AUTOSAR XML (schema 00048)
package /ComponentTypes
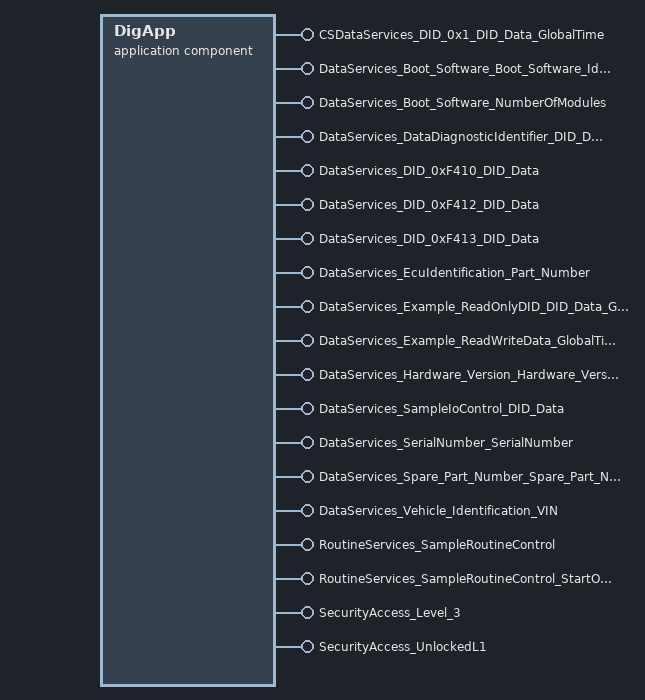
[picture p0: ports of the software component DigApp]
  application sw component type DigApp
    19 x provide port:
      CSDataServices_DID_0x1_DID_Data_GlobalTime: server-com-spec{operation=ReadData, queue-length=1}, provided-interface=CSDataServices_DID_0x1_DID_Data_GlobalTime
      DataServices_Boot_Software_Boot_Software_Identification: provided-interface=DataServices_Boot_Software_Boot_Software_Identification
        provided-com-specs:
          operation=WriteData, queue-length=1
          operation=ConditionCheckRead, queue-length=1
          operation=ReadData, queue-length=1
      DataServices_Boot_Software_NumberOfModules: provided-interface=DataServices_Boot_Software_NumberOfModules
        provided-com-specs:
          operation=WriteData, queue-length=1
          operation=ConditionCheckRead, queue-length=1
          operation=ReadData, queue-length=1
      DataServices_DataDiagnosticIdentifier_DID_DataDiagnosticIdentifier: provided-interface=DataServices_DataDiagnosticIdentifier_DID_DataDiagnosticIdentifier
        provided-com-specs:
          operation=WriteData, queue-length=1
          operation=ConditionCheckRead, queue-length=1
          operation=ReadData, queue-length=1
      DataServices_DID_0xF410_DID_Data: provided-com-specs=[{operation=ConditionCheckRead, queue-length=1}, {operation=ReadData, queue-length=1}], provided-interface=DataServices_DID_0xF410_DID_Data
      DataServices_DID_0xF412_DID_Data: provided-com-specs=[{operation=ConditionCheckRead, queue-length=1}, {operation=ReadData, queue-length=1}], provided-interface=DataServices_DID_0xF412_DID_Data
      DataServices_DID_0xF413_DID_Data: provided-com-specs=[{operation=ConditionCheckRead, queue-length=1}, {operation=ReadData, queue-length=1}], provided-interface=DataServices_DID_0xF413_DID_Data
      DataServices_EcuIdentification_Part_Number: provided-interface=DataServices_EcuIdentification_Part_Number
        provided-com-specs:
          operation=WriteData, queue-length=1
          operation=ConditionCheckRead, queue-length=1
          operation=ReadData, queue-length=1
      DataServices_Example_ReadOnlyDID_DID_Data_GlobalTime: provided-com-specs=[{operation=ConditionCheckRead, queue-length=1}, {operation=ReadData, queue-length=1}], provided-interface=DataServices_Example_ReadOnlyDID_DID_Data_GlobalTime
      DataServices_Example_ReadWriteData_GlobalTime: provided-interface=DataServices_Example_ReadWriteData_GlobalTime
        provided-com-specs:
          operation=WriteData, queue-length=1
          operation=ConditionCheckRead, queue-length=1
          operation=ReadData, queue-length=1
      DataServices_Hardware_Version_Hardware_Version_Number: provided-interface=DataServices_Hardware_Version_Hardware_Version_Number
        provided-com-specs:
          operation=WriteData, queue-length=1
          operation=ConditionCheckRead, queue-length=1
          operation=ReadData, queue-length=1
      DataServices_SampleIoControl_DID_Data: provided-interface=DataServices_SampleIoControl_DID_Data
        provided-com-specs:
          operation=ShortTermAdjustment, queue-length=1
          operation=FreezeCurrentState, queue-length=1
          operation=ResetToDefault, queue-length=1
          operation=ReturnControlToECU, queue-length=1
          operation=ReadData, queue-length=1
      DataServices_SerialNumber_SerialNumber: provided-interface=DataServices_SerialNumber_SerialNumber
        provided-com-specs:
          operation=WriteData, queue-length=1
          operation=ConditionCheckRead, queue-length=1
          operation=ReadData, queue-length=1
      DataServices_Spare_Part_Number_Spare_Part_Number: provided-interface=DataServices_Spare_Part_Number_Spare_Part_Number
        provided-com-specs:
          operation=WriteData, queue-length=1
          operation=ConditionCheckRead, queue-length=1
          operation=ReadData, queue-length=1
      DataServices_Vehicle_Identification_VIN: provided-interface=DataServices_Vehicle_Identification_VIN
        provided-com-specs:
          operation=WriteData, queue-length=1
          operation=ConditionCheckRead, queue-length=1
          operation=ReadData, queue-length=1
      RoutineServices_SampleRoutineControl: provided-interface=RoutineServices_SampleRoutineControl
        provided-com-specs:
          operation=RequestResults, queue-length=1
          operation=Stop, queue-length=1
          operation=Start, queue-length=1
      RoutineServices_SampleRoutineControl_StartOnly: provided-com-specs=[{operation=RequestResults, queue-length=1}, {operation=Start, queue-length=1}], provided-interface=RoutineServices_SampleRoutineControl_StartOnly
      SecurityAccess_Level_3: provided-com-specs=[{operation=CompareKey, queue-length=1}, {operation=GetSeed, queue-length=1}], provided-interface=SecurityAccess_Level_3
      SecurityAccess_UnlockedL1: provided-com-specs=[{operation=CompareKey, queue-length=1}, {operation=GetSeed, queue-length=1}], provided-interface=SecurityAccess_UnlockedL1
    behavior DigApp_InternalBehavior
      init event Dig_InitEvent: start-on-event=Dig_Init
      50 x operation invoked event:
        OIT_DataServices_Spare_Part_Number_Spare_Part_Number_WriteData_DataServices_Spare_Part_Number_Spare_Part_Number_WriteData: start-on-event=DataServices_Spare_Part_Number_Spare_Part_Number_WriteData, operation=DataServices_Spare_Part_Number_Spare_Part_Number.WriteData
        OIT_DataServices_Spare_Part_Number_Spare_Part_Number_ConditionCheckRead_DataServices_Spare_Part_Number_Spare_Part_NumberC28D5180: start-on-event=DataServices_Spare_Part_Number_Spare_Part_Number_ConditionCheckRead, operation=DataServices_Spare_Part_Number_Spare_Part_Number.ConditionCheckRead
        OIT_DataServices_Spare_Part_Number_Spare_Part_Number_ReadData_DataServices_Spare_Part_Number_Spare_Part_Number_ReadData: start-on-event=DataServices_Spare_Part_Number_Spare_Part_Number_ReadData, operation=DataServices_Spare_Part_Number_Spare_Part_Number.ReadData
        OIT_DataServices_Vehicle_Identification_VIN_WriteData_DataServices_Vehicle_Identification_VIN_WriteData: start-on-event=DataServices_Vehicle_Identification_VIN_WriteData, operation=DataServices_Vehicle_Identification_VIN.WriteData
        OIT_DataServices_Vehicle_Identification_VIN_ConditionCheckRead_DataServices_Vehicle_Identification_VIN_ConditionCheckRead: start-on-event=DataServices_Vehicle_Identification_VIN_ConditionCheckRead, operation=DataServices_Vehicle_Identification_VIN.ConditionCheckRead
        OIT_DataServices_Vehicle_Identification_VIN_ReadData_DataServices_Vehicle_Identification_VIN_ReadData: start-on-event=DataServices_Vehicle_Identification_VIN_ReadData, operation=DataServices_Vehicle_Identification_VIN.ReadData
        OIT_SecurityAccess_UnlockedL1_CompareKey_SecurityAccess_UnlockedL1_CompareKey: start-on-event=SecurityAccess_UnlockedL1_CompareKey, operation=SecurityAccess_UnlockedL1.CompareKey
        OIT_SecurityAccess_UnlockedL1_GetSeed_SecurityAccess_UnlockedL1_GetSeed: start-on-event=SecurityAccess_UnlockedL1_GetSeed, operation=SecurityAccess_UnlockedL1.GetSeed
        OIT_DataServices_DID_0xF413_DID_Data_ConditionCheckRead_DataServices_DID_0xF413_DID_Data_ConditionCheckRead: start-on-event=DataServices_DID_0xF413_DID_Data_ConditionCheckRead, operation=DataServices_DID_0xF413_DID_Data.ConditionCheckRead
        OIT_DataServices_DID_0xF413_DID_Data_ReadData_DataServices_DID_0xF413_DID_Data_ReadData: start-on-event=DataServices_DID_0xF413_DID_Data_ReadData, operation=DataServices_DID_0xF413_DID_Data.ReadData
        OIT_DataServices_Boot_Software_NumberOfModules_WriteData_DataServices_Boot_Software_NumberOfModules_WriteData: start-on-event=DataServices_Boot_Software_NumberOfModules_WriteData, operation=DataServices_Boot_Software_NumberOfModules.WriteData
        OIT_DataServices_Boot_Software_NumberOfModules_ConditionCheckRead_DataServices_Boot_Software_NumberOfModules_ConditionCheckRead: start-on-event=DataServices_Boot_Software_NumberOfModules_ConditionCheckRead, operation=DataServices_Boot_Software_NumberOfModules.ConditionCheckRead
        OIT_DataServices_Boot_Software_NumberOfModules_ReadData_DataServices_Boot_Software_NumberOfModules_ReadData: start-on-event=DataServices_Boot_Software_NumberOfModules_ReadData, operation=DataServices_Boot_Software_NumberOfModules.ReadData
        OIT_DataServices_DID_0xF412_DID_Data_ConditionCheckRead_DataServices_DID_0xF412_DID_Data_ConditionCheckRead: start-on-event=DataServices_DID_0xF412_DID_Data_ConditionCheckRead, operation=DataServices_DID_0xF412_DID_Data.ConditionCheckRead
        OIT_DataServices_DID_0xF412_DID_Data_ReadData_DataServices_DID_0xF412_DID_Data_ReadData: start-on-event=DataServices_DID_0xF412_DID_Data_ReadData, operation=DataServices_DID_0xF412_DID_Data.ReadData
        OIT_DataServices_SerialNumber_SerialNumber_WriteData_DataServices_SerialNumber_SerialNumber_WriteData: start-on-event=DataServices_SerialNumber_SerialNumber_WriteData, operation=DataServices_SerialNumber_SerialNumber.WriteData
        OIT_DataServices_SerialNumber_SerialNumber_ConditionCheckRead_DataServices_SerialNumber_SerialNumber_ConditionCheckRead: start-on-event=DataServices_SerialNumber_SerialNumber_ConditionCheckRead, operation=DataServices_SerialNumber_SerialNumber.ConditionCheckRead
        OIT_DataServices_SerialNumber_SerialNumber_ReadData_DataServices_SerialNumber_SerialNumber_ReadData: start-on-event=DataServices_SerialNumber_SerialNumber_ReadData, operation=DataServices_SerialNumber_SerialNumber.ReadData
        OIT_DataServices_DataDiagnosticIdentifier_DID_DataDiagnosticIdentifier_WriteData_DataServices_DataDiagnosticIdentifier_D1EF3D720: start-on-event=DataServices_DataDiagnosticIdentifier_DID_DataDiagnosticIdentifier_WriteData, operation=DataServices_DataDiagnosticIdentifier_DID_DataDiagnosticIdentifier.WriteData
        OIT_DataServices_DataDiagnosticIdentifier_DID_DataDiagnosticIdentifier_ConditionCheckRead_DataServices_DataDiagnosticIdeCC6C9644: start-on-event=DataServices_DataDiagnosticIdentifier_DID_DataDiagnosticIdentifier_ConditionCheckRead, operation=DataServices_DataDiagnosticIdentifier_DID_DataDiagnosticIdentifier.ConditionCheckRead
        OIT_DataServices_DataDiagnosticIdentifier_DID_DataDiagnosticIdentifier_ReadData_DataServices_DataDiagnosticIdentifier_DID8FC9525: start-on-event=DataServices_DataDiagnosticIdentifier_DID_DataDiagnosticIdentifier_ReadData, operation=DataServices_DataDiagnosticIdentifier_DID_DataDiagnosticIdentifier.ReadData
        OIT_DataServices_Hardware_Version_Hardware_Version_Number_WriteData_DataServices_Hardware_Version_Hardware_Version_Numbe125FF288: start-on-event=DataServices_Hardware_Version_Hardware_Version_Number_WriteData, operation=DataServices_Hardware_Version_Hardware_Version_Number.WriteData
        OIT_DataServices_Hardware_Version_Hardware_Version_Number_ConditionCheckRead_DataServices_Hardware_Version_Hardware_Vers10245F7A: start-on-event=DataServices_Hardware_Version_Hardware_Version_Number_ConditionCheckRead, operation=DataServices_Hardware_Version_Hardware_Version_Number.ConditionCheckRead
        OIT_DataServices_Hardware_Version_Hardware_Version_Number_ReadData_DataServices_Hardware_Version_Hardware_Version_Number62630144: start-on-event=DataServices_Hardware_Version_Hardware_Version_Number_ReadData, operation=DataServices_Hardware_Version_Hardware_Version_Number.ReadData
        OIT_CSDataServices_DID_0x1_DID_Data_GlobalTime_ReadData_CSDataServices_DID_0x1_DID_Data_GlobalTime_ReadData: start-on-event=CSDataServices_DID_0x1_DID_Data_GlobalTime_ReadData, operation=CSDataServices_DID_0x1_DID_Data_GlobalTime.ReadData
        OIT_RoutineServices_SampleRoutineControl_RequestResults_RoutineServices_SampleRoutineControl_RequestResults: start-on-event=RoutineServices_SampleRoutineControl_RequestResults, operation=RoutineServices_SampleRoutineControl.RequestResults
        OIT_RoutineServices_SampleRoutineControl_Stop_RoutineServices_SampleRoutineControl_Stop: start-on-event=RoutineServices_SampleRoutineControl_Stop, operation=RoutineServices_SampleRoutineControl.Stop
        OIT_RoutineServices_SampleRoutineControl_Start_RoutineServices_SampleRoutineControl_Start: start-on-event=RoutineServices_SampleRoutineControl_Start, operation=RoutineServices_SampleRoutineControl.Start
        OIT_DataServices_SampleIoControl_DID_Data_ShortTermAdjustment_DataServices_SampleIoControl_DID_Data_ShortTermAdjustment: start-on-event=DataServices_SampleIoControl_DID_Data_ShortTermAdjustment, operation=DataServices_SampleIoControl_DID_Data.ShortTermAdjustment
        OIT_DataServices_SampleIoControl_DID_Data_FreezeCurrentState_DataServices_SampleIoControl_DID_Data_FreezeCurrentState: start-on-event=DataServices_SampleIoControl_DID_Data_FreezeCurrentState, operation=DataServices_SampleIoControl_DID_Data.FreezeCurrentState
        OIT_DataServices_SampleIoControl_DID_Data_ResetToDefault_DataServices_SampleIoControl_DID_Data_ResetToDefault: start-on-event=DataServices_SampleIoControl_DID_Data_ResetToDefault, operation=DataServices_SampleIoControl_DID_Data.ResetToDefault
        OIT_DataServices_SampleIoControl_DID_Data_ReturnControlToECU_DataServices_SampleIoControl_DID_Data_ReturnControlToECU: start-on-event=DataServices_SampleIoControl_DID_Data_ReturnControlToECU, operation=DataServices_SampleIoControl_DID_Data.ReturnControlToECU
        OIT_DataServices_SampleIoControl_DID_Data_ReadData_DataServices_SampleIoControl_DID_Data_ReadData: start-on-event=DataServices_SampleIoControl_DID_Data_ReadData, operation=DataServices_SampleIoControl_DID_Data.ReadData
        OIT_RoutineServices_SampleRoutineControl_StartOnly_RequestResults_RoutineServices_SampleRoutineControl_StartOnly_RequestResults: start-on-event=RoutineServices_SampleRoutineControl_StartOnly_RequestResults, operation=RoutineServices_SampleRoutineControl_StartOnly.RequestResults
        OIT_RoutineServices_SampleRoutineControl_StartOnly_Start_RoutineServices_SampleRoutineControl_StartOnly_Start: start-on-event=RoutineServices_SampleRoutineControl_StartOnly_Start, operation=RoutineServices_SampleRoutineControl_StartOnly.Start
        OIT_DataServices_DID_0xF410_DID_Data_ConditionCheckRead_DataServices_DID_0xF410_DID_Data_ConditionCheckRead: start-on-event=DataServices_DID_0xF410_DID_Data_ConditionCheckRead, operation=DataServices_DID_0xF410_DID_Data.ConditionCheckRead
        OIT_DataServices_DID_0xF410_DID_Data_ReadData_DataServices_DID_0xF410_DID_Data_ReadData: start-on-event=DataServices_DID_0xF410_DID_Data_ReadData, operation=DataServices_DID_0xF410_DID_Data.ReadData
        OIT_DataServices_EcuIdentification_Part_Number_WriteData_DataServices_EcuIdentification_Part_Number_WriteData: start-on-event=DataServices_EcuIdentification_Part_Number_WriteData, operation=DataServices_EcuIdentification_Part_Number.WriteData
        OIT_DataServices_EcuIdentification_Part_Number_ConditionCheckRead_DataServices_EcuIdentification_Part_Number_ConditionCheckRead: start-on-event=DataServices_EcuIdentification_Part_Number_ConditionCheckRead, operation=DataServices_EcuIdentification_Part_Number.ConditionCheckRead
        OIT_DataServices_EcuIdentification_Part_Number_ReadData_DataServices_EcuIdentification_Part_Number_ReadData: start-on-event=DataServices_EcuIdentification_Part_Number_ReadData, operation=DataServices_EcuIdentification_Part_Number.ReadData
        OIT_DataServices_Example_ReadOnlyDID_DID_Data_GlobalTime_ConditionCheckRead_DataServices_Example_ReadOnlyDID_DID_Data_GlF3340FE2: start-on-event=DataServices_Example_ReadOnlyDID_DID_Data_GlobalTime_ConditionCheckRead, operation=DataServices_Example_ReadOnlyDID_DID_Data_GlobalTime.ConditionCheckRead
        OIT_DataServices_Example_ReadOnlyDID_DID_Data_GlobalTime_ReadData_DataServices_Example_ReadOnlyDID_DID_Data_GlobalTime_ReadData: start-on-event=DataServices_Example_ReadOnlyDID_DID_Data_GlobalTime_ReadData, operation=DataServices_Example_ReadOnlyDID_DID_Data_GlobalTime.ReadData
        OIT_SecurityAccess_Level_3_CompareKey_SecurityAccess_Level_3_CompareKey: start-on-event=SecurityAccess_Level_3_CompareKey, operation=SecurityAccess_Level_3.CompareKey
        OIT_SecurityAccess_Level_3_GetSeed_SecurityAccess_Level_3_GetSeed: start-on-event=SecurityAccess_Level_3_GetSeed, operation=SecurityAccess_Level_3.GetSeed
        OIT_DataServices_Boot_Software_Boot_Software_Identification_WriteData_DataServices_Boot_Software_Boot_Software_Identific0F39F5E2: start-on-event=DataServices_Boot_Software_Boot_Software_Identification_WriteData, operation=DataServices_Boot_Software_Boot_Software_Identification.WriteData
        OIT_DataServices_Boot_Software_Boot_Software_Identification_ConditionCheckRead_DataServices_Boot_Software_Boot_Software_F4268183: start-on-event=DataServices_Boot_Software_Boot_Software_Identification_ConditionCheckRead, operation=DataServices_Boot_Software_Boot_Software_Identification.ConditionCheckRead
        OIT_DataServices_Boot_Software_Boot_Software_Identification_ReadData_DataServices_Boot_Software_Boot_Software_Identifica719A6842: start-on-event=DataServices_Boot_Software_Boot_Software_Identification_ReadData, operation=DataServices_Boot_Software_Boot_Software_Identification.ReadData
        OIT_DataServices_Example_ReadWriteData_GlobalTime_WriteData_DataServices_Example_ReadWriteData_GlobalTime_WriteData: start-on-event=DataServices_Example_ReadWriteData_GlobalTime_WriteData, operation=DataServices_Example_ReadWriteData_GlobalTime.WriteData
        OIT_DataServices_Example_ReadWriteData_GlobalTime_ConditionCheckRead_DataServices_Example_ReadWriteData_GlobalTime_Condi7133933A: start-on-event=DataServices_Example_ReadWriteData_GlobalTime_ConditionCheckRead, operation=DataServices_Example_ReadWriteData_GlobalTime.ConditionCheckRead
        OIT_DataServices_Example_ReadWriteData_GlobalTime_ReadData_DataServices_Example_ReadWriteData_GlobalTime_ReadData: start-on-event=DataServices_Example_ReadWriteData_GlobalTime_ReadData, operation=DataServices_Example_ReadWriteData_GlobalTime.ReadData
      51 x runnable:
        Dig_Init
        DataServices_Spare_Part_Number_Spare_Part_Number_WriteData
        DataServices_Spare_Part_Number_Spare_Part_Number_ConditionCheckRead
        DataServices_Spare_Part_Number_Spare_Part_Number_ReadData
        DataServices_Vehicle_Identification_VIN_WriteData
        DataServices_Vehicle_Identification_VIN_ConditionCheckRead
        DataServices_Vehicle_Identification_VIN_ReadData
        SecurityAccess_UnlockedL1_CompareKey
        SecurityAccess_UnlockedL1_GetSeed
        DataServices_DID_0xF413_DID_Data_ConditionCheckRead
        DataServices_DID_0xF413_DID_Data_ReadData
        DataServices_Boot_Software_NumberOfModules_WriteData
        DataServices_Boot_Software_NumberOfModules_ConditionCheckRead
        DataServices_Boot_Software_NumberOfModules_ReadData
        DataServices_DID_0xF412_DID_Data_ConditionCheckRead
        DataServices_DID_0xF412_DID_Data_ReadData
        DataServices_SerialNumber_SerialNumber_WriteData
        DataServices_SerialNumber_SerialNumber_ConditionCheckRead
        DataServices_SerialNumber_SerialNumber_ReadData
        DataServices_DataDiagnosticIdentifier_DID_DataDiagnosticIdentifier_WriteData
        DataServices_DataDiagnosticIdentifier_DID_DataDiagnosticIdentifier_ConditionCheckRead
        DataServices_DataDiagnosticIdentifier_DID_DataDiagnosticIdentifier_ReadData
        DataServices_Hardware_Version_Hardware_Version_Number_WriteData
        DataServices_Hardware_Version_Hardware_Version_Number_ConditionCheckRead
        DataServices_Hardware_Version_Hardware_Version_Number_ReadData
        CSDataServices_DID_0x1_DID_Data_GlobalTime_ReadData
        RoutineServices_SampleRoutineControl_RequestResults
        RoutineServices_SampleRoutineControl_Stop
        RoutineServices_SampleRoutineControl_Start
        DataServices_SampleIoControl_DID_Data_ShortTermAdjustment
        DataServices_SampleIoControl_DID_Data_FreezeCurrentState
        DataServices_SampleIoControl_DID_Data_ResetToDefault
        DataServices_SampleIoControl_DID_Data_ReturnControlToECU
        DataServices_SampleIoControl_DID_Data_ReadData
        RoutineServices_SampleRoutineControl_StartOnly_RequestResults
        RoutineServices_SampleRoutineControl_StartOnly_Start
        DataServices_DID_0xF410_DID_Data_ConditionCheckRead
        DataServices_DID_0xF410_DID_Data_ReadData
        DataServices_EcuIdentification_Part_Number_WriteData
        DataServices_EcuIdentification_Part_Number_ConditionCheckRead
        DataServices_EcuIdentification_Part_Number_ReadData
        DataServices_Example_ReadOnlyDID_DID_Data_GlobalTime_ConditionCheckRead
        DataServices_Example_ReadOnlyDID_DID_Data_GlobalTime_ReadData
        SecurityAccess_Level_3_CompareKey
        SecurityAccess_Level_3_GetSeed
        DataServices_Boot_Software_Boot_Software_Identification_WriteData
        DataServices_Boot_Software_Boot_Software_Identification_ConditionCheckRead
        DataServices_Boot_Software_Boot_Software_Identification_ReadData
        DataServices_Example_ReadWriteData_GlobalTime_WriteData
        DataServices_Example_ReadWriteData_GlobalTime_ConditionCheckRead
        DataServices_Example_ReadWriteData_GlobalTime_ReadData
  swc implementation DigApp_Implementation: behavior=DigApp_InternalBehavior
